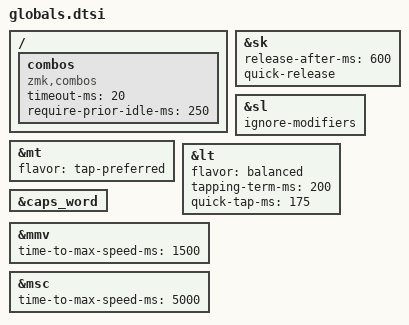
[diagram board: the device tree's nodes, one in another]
#ifndef GLOBALS_DTSI
#define GLOBALS_DTSI

#include <behaviors.dtsi>
#include <dt-bindings/zmk/keys.h>
#include <dt-bindings/zmk/pointing.h>

&sk {
  release-after-ms = <600>;
  quick-release;
};

&sl { 
  ignore-modifiers; 
};

&mt { 
  flavor = "tap-preferred"; 
};

&lt {
  flavor = "balanced";
  tapping-term-ms = <200>;
  quick-tap-ms = <175>;
};

&caps_word {
  /delete-property/ ignore-modifiers;
};

&mmv { 
  time-to-max-speed-ms = <1500>; 
};

&msc { 
  time-to-max-speed-ms = <5000>; 
};

/ {
  combos {
    compatible = "zmk,combos";
    timeout-ms = <20>;
    require-prior-idle-ms = <250>;
  };
};

#endif
